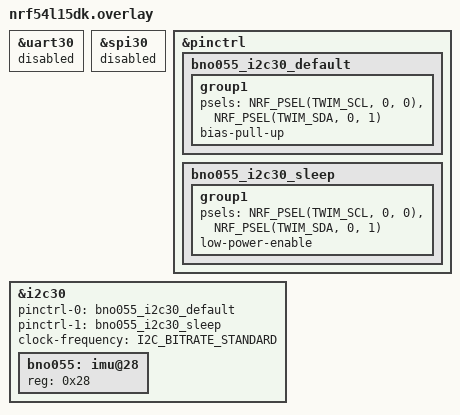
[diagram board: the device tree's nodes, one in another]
#include <zephyr/dt-bindings/i2c/i2c.h>
#include <zephyr/dt-bindings/pinctrl/nrf-pinctrl.h>

&uart30 {
    status = "disabled";
};

&spi30 {
    status = "disabled";
};

&pinctrl {
    bno055_i2c30_default: bno055_i2c30_default {
        group1 {
            psels = <NRF_PSEL(TWIM_SCL, 0, 0)>,
                    <NRF_PSEL(TWIM_SDA, 0, 1)>;
            bias-pull-up;
        };
    };

    bno055_i2c30_sleep: bno055_i2c30_sleep {
        group1 {
            psels = <NRF_PSEL(TWIM_SCL, 0, 0)>,
                    <NRF_PSEL(TWIM_SDA, 0, 1)>;
            low-power-enable;
        };
    };
};

&i2c30 {
    status = "okay";
    pinctrl-0 = <&bno055_i2c30_default>;
    pinctrl-1 = <&bno055_i2c30_sleep>;
    pinctrl-names = "default", "sleep";
    clock-frequency = <I2C_BITRATE_STANDARD>;

    bno055: imu@28 {
        reg = <0x28>;
    };
};
